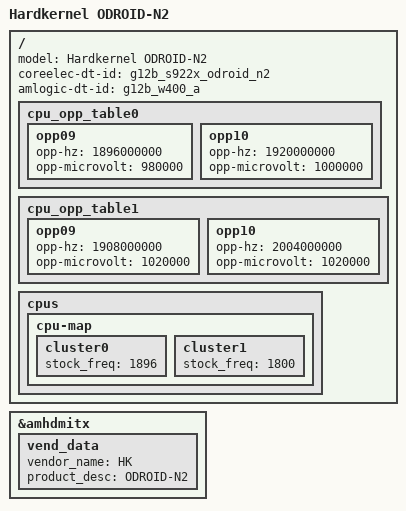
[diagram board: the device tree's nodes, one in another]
#include "g12b_s922x_odroid_n2plus.dts"
#include "coreelec_g12b_a_common.dtsi"

/ {
	model = "Hardkernel ODROID-N2";
	coreelec-dt-id = "g12b_s922x_odroid_n2";
	amlogic-dt-id = "g12b_w400_a";

	cpu_opp_table0: cpu_opp_table0 {
		opp09 {
			opp-hz = /bits/ 64 <1896000000>;
			opp-microvolt = <980000>;
		};
		opp10 {
			opp-hz = /bits/ 64 <1920000000>;
			opp-microvolt = <1000000>;
		};
	};

	cpu_opp_table1: cpu_opp_table1 {
		opp09 {
			opp-hz = /bits/ 64 <1908000000>;
			opp-microvolt = <1020000>;
		};
		opp10 {
			opp-hz = /bits/ 64 <2004000000>;
			opp-microvolt = <1020000>;
		};
		/delete-node/ opp13;
		/delete-node/ opp14;
	};

	cpus:cpus {
		cpu-map {
			cluster0:cluster0 {
				stock_freq = <1896>;
			};
			cluster1:cluster1 {
				stock_freq = <1800>;
			};
		};
	};
};

&amhdmitx {
	vend_data {
		vendor_name = "HK";
		product_desc = "ODROID-N2";
	};
};
